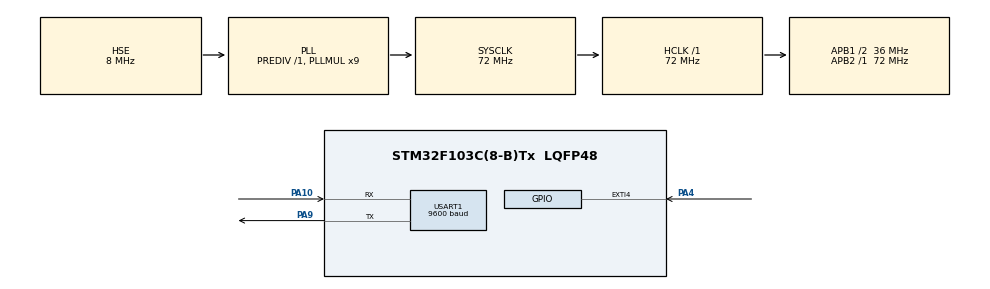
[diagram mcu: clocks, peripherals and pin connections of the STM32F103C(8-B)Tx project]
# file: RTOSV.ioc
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Mcu.Family=STM32F1
Mcu.Name=STM32F103C(8-B)Tx
Mcu.Package=LQFP48
NVIC.EXTI4_IRQn=true\:5\:0\:true\:false\:true\:true\:true\:true
NVIC.PriorityGroup=NVIC_PRIORITYGROUP_4
NVIC.TIM1_UP_IRQn=true\:15\:0\:false\:false\:true\:false\:true\:true
NVIC.TimeBase=TIM1_UP_IRQn
NVIC.TimeBaseIP=TIM1
PA10.Mode=Asynchronous
PA10.Signal=USART1_RX
PA13.Mode=Serial_Wire
PA13.Signal=SYS_JTMS-SWDIO
PA14.Mode=Serial_Wire
PA14.Signal=SYS_JTCK-SWCLK
PA4.GPIO_PuPd=GPIO_PULLUP
PA4.Signal=GPXTI4
PA9.Mode=Asynchronous
PA9.Signal=USART1_TX
PD0-OSC_IN.Mode=HSE-External-Oscillator
PD0-OSC_IN.Signal=RCC_OSC_IN
PD1-OSC_OUT.Mode=HSE-External-Oscillator
PD1-OSC_OUT.Signal=RCC_OSC_OUT
ProjectManager.HeapSize=0x200
ProjectManager.StackSize=0x400
ProjectManager.TargetToolchain=STM32CubeIDE
RCC.AHBFreq_Value=72000000
RCC.APB1CLKDivider=RCC_HCLK_DIV2
RCC.APB1Freq_Value=36000000
RCC.APB1TimFreq_Value=72000000
RCC.APB2Freq_Value=72000000
RCC.APB2TimFreq_Value=72000000
RCC.HCLKFreq_Value=72000000
RCC.PLLMUL=RCC_PLL_MUL9
RCC.PLLSourceVirtual=RCC_PLLSOURCE_HSE
RCC.SYSCLKFreq_VALUE=72000000
RCC.SYSCLKSource=RCC_SYSCLKSOURCE_PLLCLK
RCC.USBFreq_Value=72000000
USART1.BaudRate=9600
USART1.Mode=MODE_TX_RX
USART1.VirtualMode=VM_ASYNC
VP_SYS_VS_tim1.Mode=TIM1
board=custom

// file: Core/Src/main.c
/* USER CODE BEGIN Header */
/**
  ******************************************************************************
  * @file           : main.c
  * @brief          : Main program body
  ******************************************************************************
  * @attention
  *
  * Copyright (c) 2025 STMicroelectronics.
  * All rights reserved.
  *
  * This software is licensed under terms that can be found in the LICENSE file
  * in the root directory of this software component.
  * If no LICENSE file comes with this software, it is provided AS-IS.
  *
  ******************************************************************************
  */
/* USER CODE END Header */
#include "main.h"

/* USER CODE BEGIN Includes */

// FreeRTOS files
#include "FreeRTOS.h"
#include "task.h"
#include "semphr.h"
#include "queue.h"
#include "event_groups.h"

#include <stdio.h>
#include <string.h>
/* USER CODE END Includes */

/* USER CODE BEGIN PTD */
// enum to differentiate between data source
typedef enum data {
	DATA_COUNTER,
	DATA_SHARED
}data_source;

// UART Queue struct
typedef struct UART {
	data_source source;
	uint32_t data;
}UARTqueue;
/* USER CODE END PTD */

/* USER CODE BEGIN PD */
// button event group
#define BUTTON_BIT (1 << 0)
/* USER CODE END PD */

UART_HandleTypeDef huart1;

/* USER CODE BEGIN PV */
// Tasks handle
TaskHandle_t CalcSwitch1Handle = NULL;
TaskHandle_t IncreaseVarHandle = NULL;
TaskHandle_t DecreaseVarHandle = NULL;
TaskHandle_t UARTHandle = NULL;

// Queue handle
QueueHandle_t UARTdataHandle = NULL;

// Semaphore handle
SemaphoreHandle_t sharedHandle = NULL;

// event group handle
EventGroupHandle_t button_pressed = NULL;

// tasks variable
volatile uint32_t counter = 0;
volatile uint32_t shared = 100;
// debouncing variables
volatile uint32_t last_interrupt_time = 0;
const uint32_t debounce_delay = 50;
// delay in  case of busy mutex or full queue
TickType_t mutex_delay = 15;
TickType_t queue_delay = 8;
// buffer for UART message
char UART_buffer[100];

/* USER CODE END PV */

void SystemClock_Config(void);
static void MX_GPIO_Init(void);
static void MX_USART1_UART_Init(void);
/* USER CODE BEGIN PFP */
// Task function prototypes
void CalcSwitch1(void *pvParameters);
void IncreaseVar(void *pvParameters);
void DecreaseVar(void *pvParameters);
void UART(void *pvParameters);

// interrupt function
void HAL_GPIO_EXTI_Callback(uint16_t GPIO_PIN);

/* USER CODE END PFP */

int main(void)
{

  /* MCU Configuration--------------------------------------------------------*/

  /* Reset of all peripherals, Initializes the Flash interface and the Systick. */
  HAL_Init();

  /* Configure the system clock */
  SystemClock_Config();

  /* Initialize all configured peripherals */
  MX_GPIO_Init();
  MX_USART1_UART_Init();
  /* USER CODE BEGIN 2 */

  // creation of an event
  button_pressed = xEventGroupCreate();

  // Tasks creation
  xTaskCreate(CalcSwitch1, "CalcSwitch1", 128, NULL, 3, &CalcSwitch1Handle);
  xTaskCreate(IncreaseVar, "IncreaseVar", 128, NULL, 3, &IncreaseVarHandle);
  xTaskCreate(DecreaseVar, "DecreaseVar", 128, NULL, 3, &DecreaseVarHandle);
  xTaskCreate(UART, "UART", 128, NULL, 3, &UARTHandle);

  // queues creation
  UARTdataHandle = xQueueCreate(32, sizeof(UARTqueue));

  // mutex creations
  sharedHandle = xSemaphoreCreateMutex();

  // start scheduler
  vTaskStartScheduler();

  /* USER CODE END 2 */

  /* Infinite loop */
  /* USER CODE BEGIN WHILE */
  // The control mustn't reach here because the scheduler took control of the mcu
  while (1)
  {
    /* USER CODE END WHILE */

  }
}

void SystemClock_Config(void)
{
  RCC_OscInitTypeDef RCC_OscInitStruct = {0};
  RCC_ClkInitTypeDef RCC_ClkInitStruct = {0};

  /** Initializes the RCC Oscillators according to the specified parameters
  * in the RCC_OscInitTypeDef structure.
  */
  RCC_OscInitStruct.OscillatorType = RCC_OSCILLATORTYPE_HSE;
  RCC_OscInitStruct.HSEState = RCC_HSE_ON;
  RCC_OscInitStruct.HSEPredivValue = RCC_HSE_PREDIV_DIV1;
  RCC_OscInitStruct.HSIState = RCC_HSI_ON;
  RCC_OscInitStruct.PLL.PLLState = RCC_PLL_ON;
  RCC_OscInitStruct.PLL.PLLSource = RCC_PLLSOURCE_HSE;
  RCC_OscInitStruct.PLL.PLLMUL = RCC_PLL_MUL9;
  if (HAL_RCC_OscConfig(&RCC_OscInitStruct) != HAL_OK)
  {
    Error_Handler();
  }

  /** Initializes the CPU, AHB and APB buses clocks
  */
  RCC_ClkInitStruct.ClockType = RCC_CLOCKTYPE_HCLK|RCC_CLOCKTYPE_SYSCLK
                              |RCC_CLOCKTYPE_PCLK1|RCC_CLOCKTYPE_PCLK2;
  RCC_ClkInitStruct.SYSCLKSource = RCC_SYSCLKSOURCE_PLLCLK;
  RCC_ClkInitStruct.AHBCLKDivider = RCC_SYSCLK_DIV1;
  RCC_ClkInitStruct.APB1CLKDivider = RCC_HCLK_DIV2;
  RCC_ClkInitStruct.APB2CLKDivider = RCC_HCLK_DIV1;

  if (HAL_RCC_ClockConfig(&RCC_ClkInitStruct, FLASH_LATENCY_2) != HAL_OK)
  {
    Error_Handler();
  }
}

static void MX_USART1_UART_Init(void)
{

  huart1.Instance = USART1;
  huart1.Init.BaudRate = 9600;
  huart1.Init.WordLength = UART_WORDLENGTH_8B;
  huart1.Init.StopBits = UART_STOPBITS_1;
  huart1.Init.Parity = UART_PARITY_NONE;
  huart1.Init.Mode = UART_MODE_TX_RX;
  huart1.Init.HwFlowCtl = UART_HWCONTROL_NONE;
  huart1.Init.OverSampling = UART_OVERSAMPLING_16;
  if (HAL_UART_Init(&huart1) != HAL_OK)
  {
    Error_Handler();
  }

}

static void MX_GPIO_Init(void)
{
  GPIO_InitTypeDef GPIO_InitStruct = {0};

  /* GPIO Ports Clock Enable */
  __HAL_RCC_GPIOD_CLK_ENABLE();
  __HAL_RCC_GPIOA_CLK_ENABLE();

  /*Configure GPIO pin : PA4 */
  GPIO_InitStruct.Pin = GPIO_PIN_4;
  GPIO_InitStruct.Mode = GPIO_MODE_IT_RISING;
  GPIO_InitStruct.Pull = GPIO_PULLUP;
  HAL_GPIO_Init(GPIOA, &GPIO_InitStruct);

  /* EXTI interrupt init*/
  HAL_NVIC_SetPriority(EXTI4_IRQn, 5, 0);
  HAL_NVIC_EnableIRQ(EXTI4_IRQn);

}

/* USER CODE BEGIN 4 */

// interrupt function definition
void HAL_GPIO_EXTI_Callback(uint16_t GPIO_PIN) {
	if(GPIO_PIN == GPIO_PIN_4) {
		uint32_t current_time = HAL_GetTick();
		if(current_time - last_interrupt_time >= debounce_delay) {
			if(counter < 9) {
				counter++;
			}
			else {
				counter = 0;
			}
			BaseType_t xHigherPriorityTaskWoken = pdFALSE;
			xEventGroupSetBitsFromISR(button_pressed, BUTTON_BIT ,&xHigherPriorityTaskWoken);
			portYIELD_FROM_ISR(xHigherPriorityTaskWoken);
		}
		last_interrupt_time = current_time;
	}
}

// task 1 function definition
void CalcSwitch1(void *pvParameters)
{
  for(;;)
  {
	EventBits_t CalcSwitch;
	uint32_t Calc_counter = 0;
	CalcSwitch = xEventGroupWaitBits(button_pressed, BUTTON_BIT, pdTRUE, pdFALSE, 2);
	if((CalcSwitch & BUTTON_BIT) != 0) {
		Calc_counter = counter*10;
		UARTqueue Calc_UART = {DATA_COUNTER, Calc_counter};
		xQueueSend(UARTdataHandle, &Calc_UART, queue_delay);
	}

  }
}

// task 2 function definition
void IncreaseVar(void *pvParameters)
{
	TickType_t xLastWakeTime;
	const TickType_t xFrequency = 10;
	xLastWakeTime = xTaskGetTickCount();
  for(;;)
  {
	if(xSemaphoreTake(sharedHandle, mutex_delay) == pdTRUE) {
		if(shared < 200) {
			shared++;
		}
		else {
			shared = 100;
		}
		UARTqueue Increase_UART = {DATA_SHARED, shared};
		xSemaphoreGive(sharedHandle);
		xQueueSend(UARTdataHandle, &Increase_UART, queue_delay);
	}
	xTaskDelayUntil(&xLastWakeTime, xFrequency);
  }
}

// task 3 function definition
void DecreaseVar(void *pvParameters)
{
	TickType_t xLastWakeTime;
		const TickType_t xFrequency = 12;
		xLastWakeTime = xTaskGetTickCount();
  for(;;)
  {
	  if(xSemaphoreTake(sharedHandle, mutex_delay) == pdTRUE) {
	  		if(shared > 100) {
	  			shared--;
	  		}
	  		else {
	  			shared = 200;
	  		}
	  		UARTqueue Decrease_UART = {DATA_SHARED, shared};
	  		xSemaphoreGive(sharedHandle);
	  		xQueueSend(UARTdataHandle, &Decrease_UART, queue_delay);
	  }
	  xTaskDelayUntil(&xLastWakeTime, xFrequency);
  }
}

// task 4 function definition
void UART(void *pvParameters)
{
	TickType_t xLastWakeTime;
	const TickType_t xFrequency = 5;
	xLastWakeTime = xTaskGetTickCount();
  for(;;)
  {
	  UARTqueue received_message;
	  while(xQueueReceive(UARTdataHandle, &received_message, 0) == pdPASS) {
		  if(received_message.source == DATA_COUNTER) {
			  snprintf(UART_buffer, sizeof(UART_buffer), "Source: counter, Value = %lu\r\n", received_message.data);
		  }
		  else if (received_message.source == DATA_SHARED) {
			  snprintf(UART_buffer, sizeof(UART_buffer), "Source: shared, Value = %lu\r\n", received_message.data);
		  }
		  else {
			  snprintf(UART_buffer, sizeof(UART_buffer), "Source: UNKNOWN\r\n");
		  }
		  HAL_UART_Transmit(&huart1, (uint8_t*)UART_buffer, strlen(UART_buffer), 100);
	  }
	  xTaskDelayUntil(&xLastWakeTime, xFrequency);
  }
}

/* USER CODE END 4 */

void HAL_TIM_PeriodElapsedCallback(TIM_HandleTypeDef *htim)
{
  if (htim->Instance == TIM1)
  {
    HAL_IncTick();
  }
}

void Error_Handler(void)
{
  __disable_irq();
  while (1)
  {
  }
}
